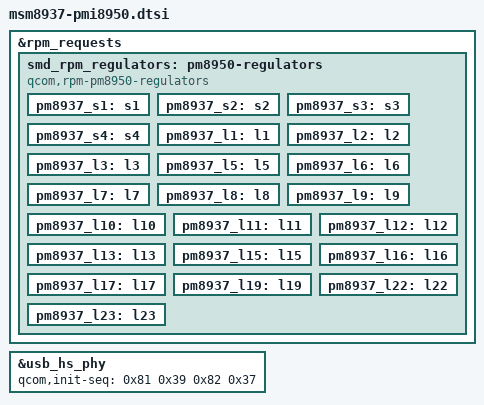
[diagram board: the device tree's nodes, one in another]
// SPDX-License-Identifier: GPL-2.0
#include "pmi8950.dtsi"

&rpm_requests {
    smd_rpm_regulators: pm8950-regulators {
        compatible = "qcom,rpm-pm8950-regulators";

        pm8937_s1: s1 {};
        pm8937_s2: s2 {};
        pm8937_s3: s3 {};
        pm8937_s4: s4 {};

        pm8937_l1: l1 {};
        pm8937_l2: l2 {};
        pm8937_l3: l3 {};
        pm8937_l5: l5 {};
        pm8937_l6: l6 {};
        pm8937_l7: l7 {};
        pm8937_l8: l8 {};
        pm8937_l9: l9 {};
        pm8937_l10: l10 {};
        pm8937_l11: l11 {};
        pm8937_l12: l12 {};
        pm8937_l13: l13 {};
        pm8937_l15: l15 {};
        pm8937_l16: l16 {};
        pm8937_l17: l17 {};
        pm8937_l19: l19 {};
        pm8937_l22: l22 {};
        pm8937_l23: l23 {};
    };
};

&usb_hs_phy {
	qcom,init-seq = /bits/ 8 <0x81 0x39 0x82 0x37>;
};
